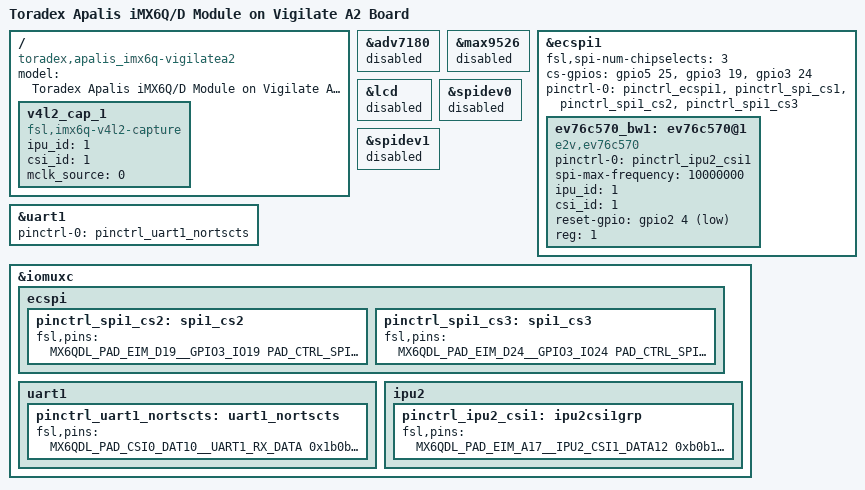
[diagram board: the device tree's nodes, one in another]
/*
 * Copyright 2014-2016 Toradex AG
 * Copyright 2012 Freescale Semiconductor, Inc.
 * Copyright 2011 Linaro Ltd.
 *
 * The code contained herein is licensed under the GNU General Public
 * License. You may obtain a copy of the GNU General Public License
 * Version 2 or later at the following locations:
 *
 * http://www.opensource.org/licenses/gpl-license.html
 * http://www.gnu.org/copyleft/gpl.html
 */

/dts-v1/;

#include <dt-bindings/input/input.h>
#include <dt-bindings/interrupt-controller/irq.h>
#include "imx6q.dtsi"
#include "imx6qdl-apalis.dtsi"
#include "imx6qdl-apalis-ixora.dtsi"

#define PAD_CTRL_SPICS 0xa1 /* PAD_CTL_SPEED_MED | PAD_CTL_DSE_80ohm | PAD_CTL_SRE_FAST */

/ {
	model = "Toradex Apalis iMX6Q/D Module on Vigilate A2 Board";
	compatible = "toradex,apalis_imx6q-vigilatea2",
		     "toradex,apalis_imx6q-ixora", "toradex,apalis_imx6q",
		     "fsl,imx6q";

        /* Add one more capture master v4l2 device */
	v4l2_cap_1 {
		compatible = "fsl,imx6q-v4l2-capture";
		ipu_id = <1>;
		csi_id = <1>;
		mclk_source = <0>;
		status = "okay";
	};
};

/* Disable adv7180 and max9526 */
&adv7180 {
		status = "disabled";
          };

&max9526 {
		status = "disabled";
         };


&ecspi1 {
	fsl,spi-num-chipselects = <3>;

	cs-gpios = <&gpio5 25 0 &gpio3 19 0 &gpio3 24 0>;
	pinctrl-names = "default";
	pinctrl-0 = <&pinctrl_ecspi1 &pinctrl_spi_cs1 &pinctrl_spi1_cs2 &pinctrl_spi1_cs3>;
	status = "okay";

	ev76c570_bw1: ev76c570@1 {
		     compatible = "e2v,ev76c570";
		     pinctrl-names = "default";
		     pinctrl-0 = <&pinctrl_ipu2_csi1>;
		     spi-max-frequency = <10000000>;
		     ipu_id = <1>;
		     csi_id = <1>;
		     reset-gpio= <&gpio2 4 GPIO_ACTIVE_LOW>;
		     reg = <1>;
		     status = "okay";
	};
};

&lcd {
	status = "disabled";
};

&spidev0 {
		 status = "disabled";
};

&spidev1 {
		 status = "disabled";
};

/* Use without hw flow control */
&uart1 {
       pinctrl-0 = <&pinctrl_uart1_nortscts>;
};

&iomuxc {
	ecspi {
	       pinctrl_spi1_cs2: spi1_cs2 {
			fsl,pins = <
				 /* SPI1 cs 2 */
				 MX6QDL_PAD_EIM_D19__GPIO3_IO19	PAD_CTRL_SPICS
			>;
		};
		pinctrl_spi1_cs3: spi1_cs3 {
			fsl,pins = <
				 /* SPI1 cs 3 */
				 MX6QDL_PAD_EIM_D24__GPIO3_IO24 PAD_CTRL_SPICS
			>;
		};
	};
	uart1 {
	      pinctrl_uart1_nortscts: uart1_nortscts {
			fsl,pins = <
				MX6QDL_PAD_CSI0_DAT10__UART1_RX_DATA 0x1b0b1
				MX6QDL_PAD_CSI0_DAT11__UART1_TX_DATA 0x1b0b1
			>;
	      };
	};
	ipu2 {
		pinctrl_ipu2_csi1: ipu2csi1grp { /* second parallel camera */
			fsl,pins = <
				MX6QDL_PAD_EIM_A17__IPU2_CSI1_DATA12       0xb0b1
				MX6QDL_PAD_EIM_A18__IPU2_CSI1_DATA13       0xb0b1
				MX6QDL_PAD_EIM_A19__IPU2_CSI1_DATA14	   0xb0b1
				MX6QDL_PAD_EIM_A20__IPU2_CSI1_DATA15       0xb0b1
				MX6QDL_PAD_EIM_A21__IPU1_DISP1_DATA16      0xb0b1
				MX6QDL_PAD_EIM_A22__IPU1_DISP1_DATA17      0xb0b1
				MX6QDL_PAD_EIM_A23__IPU1_DISP1_DATA18      0xb0b1
				MX6QDL_PAD_EIM_A24__IPU2_CSI1_DATA19       0xb0b1
				MX6QDL_PAD_EIM_A16__IPU2_CSI1_PIXCLK       0xb0b1
				MX6QDL_PAD_EIM_DA11__IPU2_CSI1_HSYNC       0xb0b1
				MX6QDL_PAD_EIM_DA12__IPU2_CSI1_VSYNC       0xb0b1
			>;
		};
	};
};
